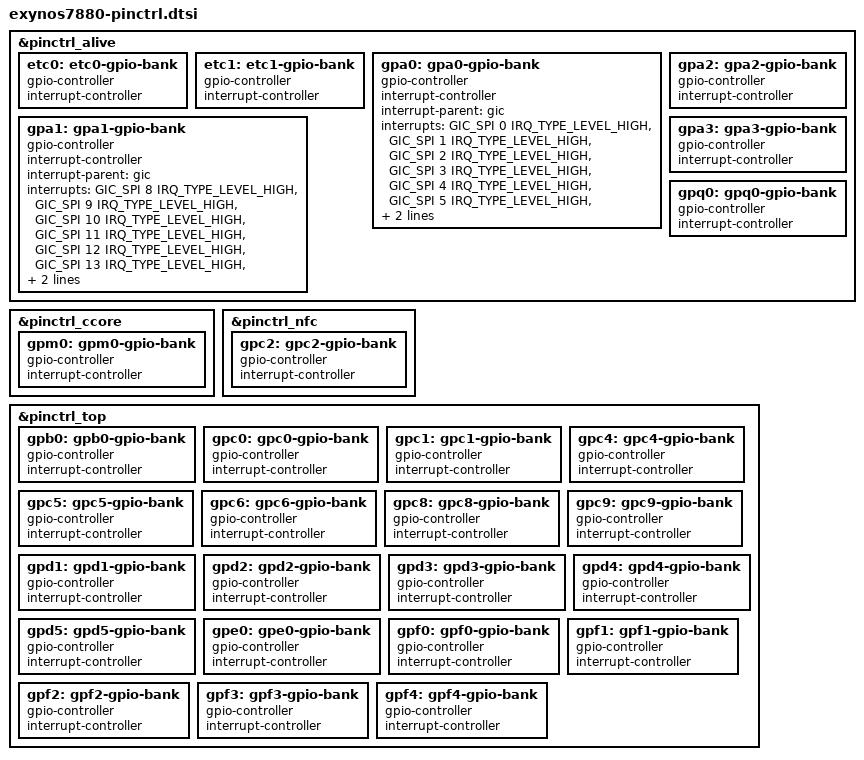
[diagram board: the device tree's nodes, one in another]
// SPDX-License-Identifier: GPL-2.0
/*
 * Samsung Exynos 7880 pin-mux and pin-config device tree source.
 *
 * M2: ALIVE controller (keys). K1: CCORE (gpm0, PMIC bus) and NFC (gpc2,
 * touch bus) controllers. M4c: TOP controller (I2C bus 0 pins for the
 * S2MU004 MUIC). Bank layout and interrupts from the Samsung universal7880
 * kernel: drivers/pinctrl/samsung/pinctrl-exynos.c exynos7880_pin_banks0/6,
 * arch/arm64/boot/dts/exynos7880.dtsi pinctrl_0 (SPI 0-15, 16), pinctrl_6
 * (SPI 438).
 */

#include <dt-bindings/interrupt-controller/arm-gic.h>
#include "exynos-pinctrl.h"

&pinctrl_alive {
	etc0: etc0-gpio-bank {
		gpio-controller;
		#gpio-cells = <2>;
		interrupt-controller;
		#interrupt-cells = <2>;
	};

	etc1: etc1-gpio-bank {
		gpio-controller;
		#gpio-cells = <2>;
		interrupt-controller;
		#interrupt-cells = <2>;
	};

	gpa0: gpa0-gpio-bank {
		gpio-controller;
		#gpio-cells = <2>;
		interrupt-controller;
		#interrupt-cells = <2>;
		interrupt-parent = <&gic>;
		interrupts = <GIC_SPI 0 IRQ_TYPE_LEVEL_HIGH>,
			     <GIC_SPI 1 IRQ_TYPE_LEVEL_HIGH>,
			     <GIC_SPI 2 IRQ_TYPE_LEVEL_HIGH>,
			     <GIC_SPI 3 IRQ_TYPE_LEVEL_HIGH>,
			     <GIC_SPI 4 IRQ_TYPE_LEVEL_HIGH>,
			     <GIC_SPI 5 IRQ_TYPE_LEVEL_HIGH>,
			     <GIC_SPI 6 IRQ_TYPE_LEVEL_HIGH>,
			     <GIC_SPI 7 IRQ_TYPE_LEVEL_HIGH>;
	};

	gpa1: gpa1-gpio-bank {
		gpio-controller;
		#gpio-cells = <2>;
		interrupt-controller;
		#interrupt-cells = <2>;
		interrupt-parent = <&gic>;
		interrupts = <GIC_SPI 8 IRQ_TYPE_LEVEL_HIGH>,
			     <GIC_SPI 9 IRQ_TYPE_LEVEL_HIGH>,
			     <GIC_SPI 10 IRQ_TYPE_LEVEL_HIGH>,
			     <GIC_SPI 11 IRQ_TYPE_LEVEL_HIGH>,
			     <GIC_SPI 12 IRQ_TYPE_LEVEL_HIGH>,
			     <GIC_SPI 13 IRQ_TYPE_LEVEL_HIGH>,
			     <GIC_SPI 14 IRQ_TYPE_LEVEL_HIGH>,
			     <GIC_SPI 15 IRQ_TYPE_LEVEL_HIGH>;
	};

	gpa2: gpa2-gpio-bank {
		gpio-controller;
		#gpio-cells = <2>;
		interrupt-controller;
		#interrupt-cells = <2>;
	};

	gpa3: gpa3-gpio-bank {
		gpio-controller;
		#gpio-cells = <2>;
		interrupt-controller;
		#interrupt-cells = <2>;
	};

	gpq0: gpq0-gpio-bank {
		gpio-controller;
		#gpio-cells = <2>;
		interrupt-controller;
		#interrupt-cells = <2>;
	};
};

&pinctrl_ccore {
	gpm0: gpm0-gpio-bank {
		gpio-controller;
		#gpio-cells = <2>;
		interrupt-controller;
		#interrupt-cells = <2>;
	};
};

&pinctrl_nfc {
	gpc2: gpc2-gpio-bank {
		gpio-controller;
		#gpio-cells = <2>;
		interrupt-controller;
		#interrupt-cells = <2>;
	};
};

&pinctrl_top {
	gpb0: gpb0-gpio-bank {
		gpio-controller;
		#gpio-cells = <2>;
		interrupt-controller;
		#interrupt-cells = <2>;
	};

	gpc0: gpc0-gpio-bank {
		gpio-controller;
		#gpio-cells = <2>;
		interrupt-controller;
		#interrupt-cells = <2>;
	};

	gpc1: gpc1-gpio-bank {
		gpio-controller;
		#gpio-cells = <2>;
		interrupt-controller;
		#interrupt-cells = <2>;
	};

	gpc4: gpc4-gpio-bank {
		gpio-controller;
		#gpio-cells = <2>;
		interrupt-controller;
		#interrupt-cells = <2>;
	};

	gpc5: gpc5-gpio-bank {
		gpio-controller;
		#gpio-cells = <2>;
		interrupt-controller;
		#interrupt-cells = <2>;
	};

	gpc6: gpc6-gpio-bank {
		gpio-controller;
		#gpio-cells = <2>;
		interrupt-controller;
		#interrupt-cells = <2>;
	};

	gpc8: gpc8-gpio-bank {
		gpio-controller;
		#gpio-cells = <2>;
		interrupt-controller;
		#interrupt-cells = <2>;
	};

	gpc9: gpc9-gpio-bank {
		gpio-controller;
		#gpio-cells = <2>;
		interrupt-controller;
		#interrupt-cells = <2>;
	};

	gpd1: gpd1-gpio-bank {
		gpio-controller;
		#gpio-cells = <2>;
		interrupt-controller;
		#interrupt-cells = <2>;
	};

	gpd2: gpd2-gpio-bank {
		gpio-controller;
		#gpio-cells = <2>;
		interrupt-controller;
		#interrupt-cells = <2>;
	};

	gpd3: gpd3-gpio-bank {
		gpio-controller;
		#gpio-cells = <2>;
		interrupt-controller;
		#interrupt-cells = <2>;
	};

	gpd4: gpd4-gpio-bank {
		gpio-controller;
		#gpio-cells = <2>;
		interrupt-controller;
		#interrupt-cells = <2>;
	};

	gpd5: gpd5-gpio-bank {
		gpio-controller;
		#gpio-cells = <2>;
		interrupt-controller;
		#interrupt-cells = <2>;
	};

	gpe0: gpe0-gpio-bank {
		gpio-controller;
		#gpio-cells = <2>;
		interrupt-controller;
		#interrupt-cells = <2>;
	};

	gpf0: gpf0-gpio-bank {
		gpio-controller;
		#gpio-cells = <2>;
		interrupt-controller;
		#interrupt-cells = <2>;
	};

	gpf1: gpf1-gpio-bank {
		gpio-controller;
		#gpio-cells = <2>;
		interrupt-controller;
		#interrupt-cells = <2>;
	};

	gpf2: gpf2-gpio-bank {
		gpio-controller;
		#gpio-cells = <2>;
		interrupt-controller;
		#interrupt-cells = <2>;
	};

	gpf3: gpf3-gpio-bank {
		gpio-controller;
		#gpio-cells = <2>;
		interrupt-controller;
		#interrupt-cells = <2>;
	};

	gpf4: gpf4-gpio-bank {
		gpio-controller;
		#gpio-cells = <2>;
		interrupt-controller;
		#interrupt-cells = <2>;
	};
};
